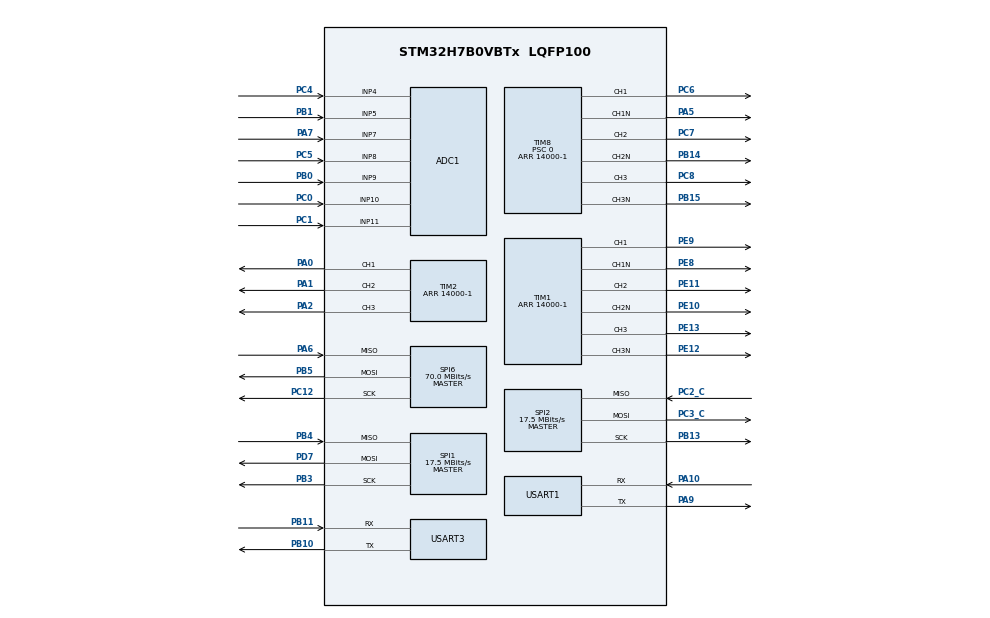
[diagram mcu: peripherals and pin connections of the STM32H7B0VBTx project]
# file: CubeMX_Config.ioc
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ADC1.Channel-0\#ChannelRegularConversion=ADC_CHANNEL_9
ADC1.Channel-1\#ChannelRegularConversion=ADC_CHANNEL_5
ADC1.Channel-2\#ChannelRegularConversion=ADC_CHANNEL_4
ADC1.Channel-3\#ChannelRegularConversion=ADC_CHANNEL_8
ADC1.Channel-4\#ChannelRegularConversion=ADC_CHANNEL_7
ADC1.Channel-5\#ChannelRegularConversion=ADC_CHANNEL_10
ADC1.Channel-6\#ChannelRegularConversion=ADC_CHANNEL_11
ADC1.ClockPrescaler=ADC_CLOCK_ASYNC_DIV2
ADC1.EnableAnalogWatchDog1=false
ADC1.ExternalTrigConv=ADC_EXTERNALTRIG_T1_TRGO
ADC1.NbrOfConversion=7
ADC1.NbrOfConversionFlag=1
ADC1.OffsetNumber-0\#ChannelRegularConversion=ADC_OFFSET_NONE
ADC1.OffsetNumber-1\#ChannelRegularConversion=ADC_OFFSET_NONE
ADC1.OffsetNumber-2\#ChannelRegularConversion=ADC_OFFSET_NONE
ADC1.OffsetNumber-3\#ChannelRegularConversion=ADC_OFFSET_NONE
ADC1.OffsetNumber-4\#ChannelRegularConversion=ADC_OFFSET_NONE
ADC1.OffsetNumber-5\#ChannelRegularConversion=ADC_OFFSET_NONE
ADC1.OffsetNumber-6\#ChannelRegularConversion=ADC_OFFSET_NONE
ADC1.OffsetSignedSaturation-0\#ChannelRegularConversion=DISABLE
ADC1.OffsetSignedSaturation-1\#ChannelRegularConversion=DISABLE
ADC1.OffsetSignedSaturation-2\#ChannelRegularConversion=DISABLE
ADC1.OffsetSignedSaturation-3\#ChannelRegularConversion=DISABLE
ADC1.OffsetSignedSaturation-4\#ChannelRegularConversion=DISABLE
ADC1.OffsetSignedSaturation-5\#ChannelRegularConversion=DISABLE
ADC1.OffsetSignedSaturation-6\#ChannelRegularConversion=DISABLE
ADC1.Rank-0\#ChannelRegularConversion=1
ADC1.Rank-1\#ChannelRegularConversion=2
ADC1.Rank-2\#ChannelRegularConversion=3
ADC1.Rank-3\#ChannelRegularConversion=4
ADC1.Rank-4\#ChannelRegularConversion=5
ADC1.Rank-5\#ChannelRegularConversion=6
ADC1.Rank-6\#ChannelRegularConversion=7
ADC1.SamplingTime-0\#ChannelRegularConversion=ADC_SAMPLETIME_1CYCLE_5
ADC1.SamplingTime-1\#ChannelRegularConversion=ADC_SAMPLETIME_1CYCLE_5
ADC1.SamplingTime-2\#ChannelRegularConversion=ADC_SAMPLETIME_1CYCLE_5
ADC1.SamplingTime-3\#ChannelRegularConversion=ADC_SAMPLETIME_1CYCLE_5
ADC1.SamplingTime-4\#ChannelRegularConversion=ADC_SAMPLETIME_1CYCLE_5
ADC1.SamplingTime-5\#ChannelRegularConversion=ADC_SAMPLETIME_1CYCLE_5
ADC1.SamplingTime-6\#ChannelRegularConversion=ADC_SAMPLETIME_1CYCLE_5
ADC1.master=1
CORTEX_M7.CPU_DCache=Enabled
CORTEX_M7.CPU_ICache=Enabled
Mcu.Family=STM32H7
Mcu.Name=STM32H7B0VBTx
Mcu.Package=LQFP100
NVIC.PriorityGroup=NVIC_PRIORITYGROUP_4
NVIC.TIM4_IRQn=true\:0\:0\:false\:false\:true\:true\:true\:true
PA0.GPIO_Speed=GPIO_SPEED_FREQ_VERY_HIGH
PA0.Signal=S_TIM2_CH1_ETR
PA1.GPIO_Speed=GPIO_SPEED_FREQ_VERY_HIGH
PA1.Signal=S_TIM2_CH2
PA10.GPIO_PuPd=GPIO_PULLUP
PA10.GPIO_Speed=GPIO_SPEED_FREQ_HIGH
PA10.Mode=Asynchronous
PA10.Signal=USART1_RX
PA13.Mode=Serial_Wire
PA13.Signal=DEBUG_JTMS-SWDIO
PA14.Mode=Serial_Wire
PA14.Signal=DEBUG_JTCK-SWCLK
PA2.GPIO_Speed=GPIO_SPEED_FREQ_VERY_HIGH
PA2.Signal=S_TIM2_CH3
PA5.GPIO_Speed=GPIO_SPEED_FREQ_VERY_HIGH
PA5.Mode=PWM Generation1 CH1 CH1N
PA5.Signal=TIM8_CH1N
PA6.Mode=Full_Duplex_Master
PA6.Signal=SPI6_MISO
PA7.Signal=ADCx_INP7
PA9.GPIO_PuPd=GPIO_PULLUP
PA9.GPIO_Speed=GPIO_SPEED_FREQ_HIGH
PA9.Mode=Asynchronous
PA9.Signal=USART1_TX
PB0.Signal=ADCx_INP9
PB1.Signal=ADCx_INP5
PB10.GPIO_PuPd=GPIO_PULLUP
PB10.GPIO_Speed=GPIO_SPEED_FREQ_HIGH
PB10.Mode=Asynchronous
PB10.Signal=USART3_TX
PB11.GPIO_PuPd=GPIO_PULLUP
PB11.GPIO_Speed=GPIO_SPEED_FREQ_HIGH
PB11.Mode=Asynchronous
PB11.Signal=USART3_RX
PB13.GPIO_PuPd=GPIO_PULLUP
PB13.GPIO_Speed=GPIO_SPEED_FREQ_VERY_HIGH
PB13.Mode=Full_Duplex_Master
PB13.Signal=SPI2_SCK
PB14.GPIO_Speed=GPIO_SPEED_FREQ_VERY_HIGH
PB14.Mode=PWM Generation2 CH2 CH2N
PB14.Signal=TIM8_CH2N
PB15.GPIO_Speed=GPIO_SPEED_FREQ_VERY_HIGH
PB15.Mode=PWM Generation3 CH3 CH3N
PB15.Signal=TIM8_CH3N
PB3.GPIO_PuPd=GPIO_PULLUP
PB3.GPIO_Speed=GPIO_SPEED_FREQ_HIGH
PB3.Mode=Full_Duplex_Master
PB3.Signal=SPI1_SCK
PB4.GPIO_PuPd=GPIO_PULLUP
PB4.GPIO_Speed=GPIO_SPEED_FREQ_HIGH
PB4.Mode=Full_Duplex_Master
PB4.Signal=SPI1_MISO
PB5.Mode=Full_Duplex_Master
PB5.Signal=SPI6_MOSI
PC0.Signal=ADCx_INP10
PC1.Signal=ADCx_INP11
PC12.Mode=Full_Duplex_Master
PC12.Signal=SPI6_SCK
PC2_C.GPIO_PuPd=GPIO_PULLUP
PC2_C.GPIO_Speed=GPIO_SPEED_FREQ_VERY_HIGH
PC2_C.Mode=Full_Duplex_Master
PC2_C.Signal=SPI2_MISO
PC3_C.GPIO_PuPd=GPIO_PULLUP
PC3_C.GPIO_Speed=GPIO_SPEED_FREQ_VERY_HIGH
PC3_C.Mode=Full_Duplex_Master
PC3_C.Signal=SPI2_MOSI
PC4.Signal=ADCx_INP4
PC5.Signal=ADCx_INP8
PC6.GPIO_Speed=GPIO_SPEED_FREQ_VERY_HIGH
PC6.Signal=S_TIM8_CH1
PC7.GPIO_Speed=GPIO_SPEED_FREQ_VERY_HIGH
PC7.Signal=S_TIM8_CH2
PC8.GPIO_Speed=GPIO_SPEED_FREQ_VERY_HIGH
PC8.Signal=S_TIM8_CH3
PD7.GPIO_PuPd=GPIO_PULLUP
PD7.GPIO_Speed=GPIO_SPEED_FREQ_HIGH
PD7.Mode=Full_Duplex_Master
PD7.Signal=SPI1_MOSI
PE10.GPIO_Speed=GPIO_SPEED_FREQ_VERY_HIGH
PE10.Mode=PWM Generation2 CH2 CH2N
PE10.Signal=TIM1_CH2N
PE11.GPIO_Speed=GPIO_SPEED_FREQ_VERY_HIGH
PE11.Signal=S_TIM1_CH2
PE12.GPIO_Speed=GPIO_SPEED_FREQ_VERY_HIGH
PE12.Mode=PWM Generation3 CH3 CH3N
PE12.Signal=TIM1_CH3N
PE13.GPIO_Speed=GPIO_SPEED_FREQ_VERY_HIGH
PE13.Signal=S_TIM1_CH3
PE8.GPIO_Speed=GPIO_SPEED_FREQ_VERY_HIGH
PE8.Mode=PWM Generation1 CH1 CH1N
PE8.Signal=TIM1_CH1N
PE9.GPIO_Speed=GPIO_SPEED_FREQ_VERY_HIGH
PE9.Signal=S_TIM1_CH1
PH0-OSC_IN.Mode=HSE-External-Oscillator
PH0-OSC_IN.Signal=RCC_OSC_IN
PH1-OSC_OUT.Mode=HSE-External-Oscillator
PH1-OSC_OUT.Signal=RCC_OSC_OUT
ProjectManager.HeapSize=0x200
ProjectManager.StackSize=0x400
ProjectManager.TargetToolchain=MDK-ARM V5.32
RCC.ADCFreq_Value=42667100.69444445
RCC.APB1Freq_Value=140000000
RCC.APB2Freq_Value=140000000
RCC.APB3Freq_Value=140000000
RCC.APB4Freq_Value=140000000
RCC.CDPPRE=RCC_APB3_DIV2
RCC.CDPPRE1=RCC_APB1_DIV2
RCC.CDPPRE2=RCC_APB2_DIV2
RCC.CKPERSourceSelection=RCC_CLKPSOURCE_HSE
RCC.CortexFreq_Value=280000000
RCC.DIVM1=3
RCC.DIVM2=3
RCC.DIVN1=42
RCC.DIVN2=9
RCC.DIVP2=3
RCC.DIVQ1=4
RCC.HCLKFreq_Value=280000000
RCC.HSE_VALUE=40000000
RCC.PLL2FRACN=4916
RCC.PLL3FRACN=0
RCC.PLLFRACN=0
RCC.PLLSourceVirtual=RCC_PLLSOURCE_HSE
RCC.SRDPPRE=RCC_APB4_DIV2
RCC.SYSCLKFreq_VALUE=280000000
RCC.SYSCLKSource=RCC_SYSCLKSOURCE_PLLCLK
RCC.USBFreq_Value=140000000
SH.ADCx_INP10.0=ADC1_INP10,IN10-Single-Ended
SH.ADCx_INP11.0=ADC1_INP11,IN11-Single-Ended
SH.ADCx_INP4.0=ADC1_INP4,IN4-Single-Ended
SH.ADCx_INP5.0=ADC1_INP5,IN5-Single-Ended
SH.ADCx_INP7.0=ADC1_INP7,IN7-Single-Ended
SH.ADCx_INP8.0=ADC1_INP8,IN8-Single-Ended
SH.ADCx_INP9.0=ADC1_INP9,IN9-Single-Ended
SH.S_TIM1_CH1.0=TIM1_CH1,PWM Generation1 CH1 CH1N
SH.S_TIM1_CH2.0=TIM1_CH2,PWM Generation2 CH2 CH2N
SH.S_TIM1_CH3.0=TIM1_CH3,PWM Generation3 CH3 CH3N
SH.S_TIM2_CH1_ETR.0=TIM2_CH1,PWM Generation1 CH1
SH.S_TIM2_CH2.0=TIM2_CH2,PWM Generation2 CH2
SH.S_TIM2_CH3.0=TIM2_CH3,PWM Generation3 CH3
SH.S_TIM8_CH1.0=TIM8_CH1,PWM Generation1 CH1 CH1N
SH.S_TIM8_CH2.0=TIM8_CH2,PWM Generation2 CH2 CH2N
SH.S_TIM8_CH3.0=TIM8_CH3,PWM Generation3 CH3 CH3N
SPI1.BaudRatePrescaler=SPI_BAUDRATEPRESCALER_8
SPI1.CLKPhase=SPI_PHASE_2EDGE
SPI1.CLKPolarity=SPI_POLARITY_HIGH
SPI1.CalculateBaudRate=17.5 MBits/s
SPI1.Direction=SPI_DIRECTION_2LINES
SPI1.Mode=SPI_MODE_MASTER
SPI1.VirtualType=VM_MASTER
SPI2.BaudRatePrescaler=SPI_BAUDRATEPRESCALER_8
SPI2.CalculateBaudRate=17.5 MBits/s
SPI2.Direction=SPI_DIRECTION_2LINES
SPI2.IOSwap=SPI_IO_SWAP_ENABLE
SPI2.Mode=SPI_MODE_MASTER
SPI2.VirtualType=VM_MASTER
SPI6.CalculateBaudRate=70.0 MBits/s
SPI6.Direction=SPI_DIRECTION_2LINES
SPI6.Mode=SPI_MODE_MASTER
SPI6.VirtualType=VM_MASTER
TIM1.Channel-PWM\ Generation1\ CH1\ CH1N=TIM_CHANNEL_1
TIM1.Channel-PWM\ Generation2\ CH2\ CH2N=TIM_CHANNEL_2
TIM1.Channel-PWM\ Generation3\ CH3\ CH3N=TIM_CHANNEL_3
TIM1.Channel-PWM\ Generation4\ No\ Output=TIM_CHANNEL_4
TIM1.CounterMode=TIM_COUNTERMODE_CENTERALIGNED1
TIM1.OCMode_PWM-PWM\ Generation4\ No\ Output=TIM_OCMODE_PWM2
TIM1.Period=14000-1
TIM1.TIM_MasterOutputTrigger=TIM_TRGO_OC4REF
TIM2.Channel-PWM\ Generation1\ CH1=TIM_CHANNEL_1
TIM2.Channel-PWM\ Generation2\ CH2=TIM_CHANNEL_2
TIM2.Channel-PWM\ Generation3\ CH3=TIM_CHANNEL_3
TIM2.Period=14000-1
TIM2.Pulse-PWM\ Generation1\ CH1=7000-1
TIM2.Pulse-PWM\ Generation2\ CH2=7000-1
TIM2.Pulse-PWM\ Generation3\ CH3=7000-1
TIM8.AutomaticOutput=TIM_AUTOMATICOUTPUT_ENABLE
TIM8.Channel-PWM\ Generation1\ CH1\ CH1N=TIM_CHANNEL_1
TIM8.Channel-PWM\ Generation2\ CH2\ CH2N=TIM_CHANNEL_2
TIM8.Channel-PWM\ Generation3\ CH3\ CH3N=TIM_CHANNEL_3
TIM8.DeadTime=48
TIM8.LockLevel=TIM_LOCKLEVEL_3
TIM8.Period=14000-1
TIM8.Prescaler=0
TIM8.Pulse-PWM\ Generation1\ CH1\ CH1N=7000-1
USART1.VirtualMode-Asynchronous=VM_ASYNC
USART3.VirtualMode-Asynchronous=VM_ASYNC
VP_TIM1_VS_ClockSourceINT.Mode=Internal
VP_TIM1_VS_no_output4.Mode=PWM Generation4 No Output
VP_TIM2_VS_ClockSourceINT.Mode=Internal
VP_TIM4_VS_ClockSourceINT.Mode=Internal
VP_TIM8_VS_ClockSourceINT.Mode=Internal
board=custom

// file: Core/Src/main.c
/* USER CODE BEGIN Header */
/**
  ******************************************************************************
  * @file           : main.c
  * @brief          : Main program body
  ******************************************************************************
  * @attention
  *
  * Copyright (c) 2024 STMicroelectronics.
  * All rights reserved.
  *
  * This software is licensed under terms that can be found in the LICENSE file
  * in the root directory of this software component.
  * If no LICENSE file comes with this software, it is provided AS-IS.
  *
  ******************************************************************************
  */
/* USER CODE END Header */
#include "main.h"

ADC_HandleTypeDef hadc1;

SPI_HandleTypeDef hspi1;
SPI_HandleTypeDef hspi2;
SPI_HandleTypeDef hspi6;

TIM_HandleTypeDef htim1;
TIM_HandleTypeDef htim2;
TIM_HandleTypeDef htim4;
TIM_HandleTypeDef htim8;

UART_HandleTypeDef huart1;
UART_HandleTypeDef huart3;

void SystemClock_Config(void);
static void MX_GPIO_Init(void);
static void MX_USART3_UART_Init(void);
static void MX_SPI1_Init(void);
static void MX_SPI6_Init(void);
static void MX_USART1_UART_Init(void);
static void MX_TIM8_Init(void);
static void MX_TIM1_Init(void);
static void MX_TIM2_Init(void);
static void MX_ADC1_Init(void);
static void MX_SPI2_Init(void);
static void MX_TIM4_Init(void);

int main(void)
{

  /* Enable I-Cache---------------------------------------------------------*/
  SCB_EnableICache();

  /* Enable D-Cache---------------------------------------------------------*/
  SCB_EnableDCache();

  /* MCU Configuration--------------------------------------------------------*/

  /* Reset of all peripherals, Initializes the Flash interface and the Systick. */
  HAL_Init();

  /* Configure the system clock */
  SystemClock_Config();

  /* Initialize all configured peripherals */
  MX_GPIO_Init();
  MX_USART3_UART_Init();
  MX_SPI1_Init();
  MX_SPI6_Init();
  MX_USART1_UART_Init();
  MX_TIM8_Init();
  MX_TIM1_Init();
  MX_TIM2_Init();
  MX_ADC1_Init();
  MX_SPI2_Init();
  MX_TIM4_Init();

  /* Infinite loop */
  while (1)
  {

  }
}

void SystemClock_Config(void)
{
  RCC_OscInitTypeDef RCC_OscInitStruct = {0};
  RCC_ClkInitTypeDef RCC_ClkInitStruct = {0};

  /*AXI clock gating */
  RCC->CKGAENR = 0xFFFFFFFF;

  /** Supply configuration update enable
  */
  HAL_PWREx_ConfigSupply(PWR_LDO_SUPPLY);

  /** Configure the main internal regulator output voltage
  */
  __HAL_PWR_VOLTAGESCALING_CONFIG(PWR_REGULATOR_VOLTAGE_SCALE0);

  while(!__HAL_PWR_GET_FLAG(PWR_FLAG_VOSRDY)) {}

  /** Initializes the RCC Oscillators according to the specified parameters
  * in the RCC_OscInitTypeDef structure.
  */
  RCC_OscInitStruct.OscillatorType = RCC_OSCILLATORTYPE_HSE;
  RCC_OscInitStruct.HSEState = RCC_HSE_ON;
  RCC_OscInitStruct.PLL.PLLState = RCC_PLL_ON;
  RCC_OscInitStruct.PLL.PLLSource = RCC_PLLSOURCE_HSE;
  RCC_OscInitStruct.PLL.PLLM = 3;
  RCC_OscInitStruct.PLL.PLLN = 42;
  RCC_OscInitStruct.PLL.PLLP = 2;
  RCC_OscInitStruct.PLL.PLLQ = 4;
  RCC_OscInitStruct.PLL.PLLR = 2;
  RCC_OscInitStruct.PLL.PLLRGE = RCC_PLL1VCIRANGE_3;
  RCC_OscInitStruct.PLL.PLLVCOSEL = RCC_PLL1VCOWIDE;
  RCC_OscInitStruct.PLL.PLLFRACN = 0;
  if (HAL_RCC_OscConfig(&RCC_OscInitStruct) != HAL_OK)
  {
    Error_Handler();
  }

  /** Initializes the CPU, AHB and APB buses clocks
  */
  RCC_ClkInitStruct.ClockType = RCC_CLOCKTYPE_HCLK|RCC_CLOCKTYPE_SYSCLK
                              |RCC_CLOCKTYPE_PCLK1|RCC_CLOCKTYPE_PCLK2
                              |RCC_CLOCKTYPE_D3PCLK1|RCC_CLOCKTYPE_D1PCLK1;
  RCC_ClkInitStruct.SYSCLKSource = RCC_SYSCLKSOURCE_PLLCLK;
  RCC_ClkInitStruct.SYSCLKDivider = RCC_SYSCLK_DIV1;
  RCC_ClkInitStruct.AHBCLKDivider = RCC_HCLK_DIV1;
  RCC_ClkInitStruct.APB3CLKDivider = RCC_APB3_DIV2;
  RCC_ClkInitStruct.APB1CLKDivider = RCC_APB1_DIV2;
  RCC_ClkInitStruct.APB2CLKDivider = RCC_APB2_DIV2;
  RCC_ClkInitStruct.APB4CLKDivider = RCC_APB4_DIV2;

  if (HAL_RCC_ClockConfig(&RCC_ClkInitStruct, FLASH_LATENCY_6) != HAL_OK)
  {
    Error_Handler();
  }
}

static void MX_ADC1_Init(void)
{

  ADC_MultiModeTypeDef multimode = {0};
  ADC_ChannelConfTypeDef sConfig = {0};

  /** Common config
  */
  hadc1.Instance = ADC1;
  hadc1.Init.ClockPrescaler = ADC_CLOCK_ASYNC_DIV2;
  hadc1.Init.Resolution = ADC_RESOLUTION_16B;
  hadc1.Init.ScanConvMode = ADC_SCAN_ENABLE;
  hadc1.Init.EOCSelection = ADC_EOC_SINGLE_CONV;
  hadc1.Init.LowPowerAutoWait = DISABLE;
  hadc1.Init.ContinuousConvMode = DISABLE;
  hadc1.Init.NbrOfConversion = 7;
  hadc1.Init.DiscontinuousConvMode = DISABLE;
  hadc1.Init.ExternalTrigConv = ADC_EXTERNALTRIG_T1_TRGO;
  hadc1.Init.ExternalTrigConvEdge = ADC_EXTERNALTRIGCONVEDGE_RISING;
  hadc1.Init.ConversionDataManagement = ADC_CONVERSIONDATA_DR;
  hadc1.Init.Overrun = ADC_OVR_DATA_PRESERVED;
  hadc1.Init.LeftBitShift = ADC_LEFTBITSHIFT_NONE;
  hadc1.Init.OversamplingMode = DISABLE;
  if (HAL_ADC_Init(&hadc1) != HAL_OK)
  {
    Error_Handler();
  }

  /** Configure the ADC multi-mode
  */
  multimode.Mode = ADC_MODE_INDEPENDENT;
  if (HAL_ADCEx_MultiModeConfigChannel(&hadc1, &multimode) != HAL_OK)
  {
    Error_Handler();
  }

  /** Configure Regular Channel
  */
  sConfig.Channel = ADC_CHANNEL_9;
  sConfig.Rank = ADC_REGULAR_RANK_1;
  sConfig.SamplingTime = ADC_SAMPLETIME_1CYCLE_5;
  sConfig.SingleDiff = ADC_SINGLE_ENDED;
  sConfig.OffsetNumber = ADC_OFFSET_NONE;
  sConfig.Offset = 0;
  sConfig.OffsetSignedSaturation = DISABLE;
  if (HAL_ADC_ConfigChannel(&hadc1, &sConfig) != HAL_OK)
  {
    Error_Handler();
  }

  /** Configure Regular Channel
  */
  sConfig.Channel = ADC_CHANNEL_5;
  sConfig.Rank = ADC_REGULAR_RANK_2;
  if (HAL_ADC_ConfigChannel(&hadc1, &sConfig) != HAL_OK)
  {
    Error_Handler();
  }

  /** Configure Regular Channel
  */
  sConfig.Channel = ADC_CHANNEL_4;
  sConfig.Rank = ADC_REGULAR_RANK_3;
  if (HAL_ADC_ConfigChannel(&hadc1, &sConfig) != HAL_OK)
  {
    Error_Handler();
  }

  /** Configure Regular Channel
  */
  sConfig.Channel = ADC_CHANNEL_8;
  sConfig.Rank = ADC_REGULAR_RANK_4;
  if (HAL_ADC_ConfigChannel(&hadc1, &sConfig) != HAL_OK)
  {
    Error_Handler();
  }

  /** Configure Regular Channel
  */
  sConfig.Channel = ADC_CHANNEL_7;
  sConfig.Rank = ADC_REGULAR_RANK_5;
  if (HAL_ADC_ConfigChannel(&hadc1, &sConfig) != HAL_OK)
  {
    Error_Handler();
  }

  /** Configure Regular Channel
  */
  sConfig.Channel = ADC_CHANNEL_10;
  sConfig.Rank = ADC_REGULAR_RANK_6;
  if (HAL_ADC_ConfigChannel(&hadc1, &sConfig) != HAL_OK)
  {
    Error_Handler();
  }

  /** Configure Regular Channel
  */
  sConfig.Channel = ADC_CHANNEL_11;
  sConfig.Rank = ADC_REGULAR_RANK_7;
  if (HAL_ADC_ConfigChannel(&hadc1, &sConfig) != HAL_OK)
  {
    Error_Handler();
  }

}

static void MX_SPI1_Init(void)
{

  /* SPI1 parameter configuration*/
  hspi1.Instance = SPI1;
  hspi1.Init.Mode = SPI_MODE_MASTER;
  hspi1.Init.Direction = SPI_DIRECTION_2LINES;
  hspi1.Init.DataSize = SPI_DATASIZE_4BIT;
  hspi1.Init.CLKPolarity = SPI_POLARITY_HIGH;
  hspi1.Init.CLKPhase = SPI_PHASE_2EDGE;
  hspi1.Init.NSS = SPI_NSS_SOFT;
  hspi1.Init.BaudRatePrescaler = SPI_BAUDRATEPRESCALER_8;
  hspi1.Init.FirstBit = SPI_FIRSTBIT_MSB;
  hspi1.Init.TIMode = SPI_TIMODE_DISABLE;
  hspi1.Init.CRCCalculation = SPI_CRCCALCULATION_DISABLE;
  hspi1.Init.CRCPolynomial = 0x0;
  hspi1.Init.NSSPMode = SPI_NSS_PULSE_ENABLE;
  hspi1.Init.NSSPolarity = SPI_NSS_POLARITY_LOW;
  hspi1.Init.FifoThreshold = SPI_FIFO_THRESHOLD_01DATA;
  hspi1.Init.TxCRCInitializationPattern = SPI_CRC_INITIALIZATION_ALL_ZERO_PATTERN;
  hspi1.Init.RxCRCInitializationPattern = SPI_CRC_INITIALIZATION_ALL_ZERO_PATTERN;
  hspi1.Init.MasterSSIdleness = SPI_MASTER_SS_IDLENESS_00CYCLE;
  hspi1.Init.MasterInterDataIdleness = SPI_MASTER_INTERDATA_IDLENESS_00CYCLE;
  hspi1.Init.MasterReceiverAutoSusp = SPI_MASTER_RX_AUTOSUSP_DISABLE;
  hspi1.Init.MasterKeepIOState = SPI_MASTER_KEEP_IO_STATE_DISABLE;
  hspi1.Init.IOSwap = SPI_IO_SWAP_DISABLE;
  if (HAL_SPI_Init(&hspi1) != HAL_OK)
  {
    Error_Handler();
  }

}

static void MX_SPI2_Init(void)
{

  /* SPI2 parameter configuration*/
  hspi2.Instance = SPI2;
  hspi2.Init.Mode = SPI_MODE_MASTER;
  hspi2.Init.Direction = SPI_DIRECTION_2LINES;
  hspi2.Init.DataSize = SPI_DATASIZE_4BIT;
  hspi2.Init.CLKPolarity = SPI_POLARITY_LOW;
  hspi2.Init.CLKPhase = SPI_PHASE_1EDGE;
  hspi2.Init.NSS = SPI_NSS_SOFT;
  hspi2.Init.BaudRatePrescaler = SPI_BAUDRATEPRESCALER_8;
  hspi2.Init.FirstBit = SPI_FIRSTBIT_MSB;
  hspi2.Init.TIMode = SPI_TIMODE_DISABLE;
  hspi2.Init.CRCCalculation = SPI_CRCCALCULATION_DISABLE;
  hspi2.Init.CRCPolynomial = 0x0;
  hspi2.Init.NSSPMode = SPI_NSS_PULSE_ENABLE;
  hspi2.Init.NSSPolarity = SPI_NSS_POLARITY_LOW;
  hspi2.Init.FifoThreshold = SPI_FIFO_THRESHOLD_01DATA;
  hspi2.Init.TxCRCInitializationPattern = SPI_CRC_INITIALIZATION_ALL_ZERO_PATTERN;
  hspi2.Init.RxCRCInitializationPattern = SPI_CRC_INITIALIZATION_ALL_ZERO_PATTERN;
  hspi2.Init.MasterSSIdleness = SPI_MASTER_SS_IDLENESS_00CYCLE;
  hspi2.Init.MasterInterDataIdleness = SPI_MASTER_INTERDATA_IDLENESS_00CYCLE;
  hspi2.Init.MasterReceiverAutoSusp = SPI_MASTER_RX_AUTOSUSP_DISABLE;
  hspi2.Init.MasterKeepIOState = SPI_MASTER_KEEP_IO_STATE_DISABLE;
  hspi2.Init.IOSwap = SPI_IO_SWAP_ENABLE;
  if (HAL_SPI_Init(&hspi2) != HAL_OK)
  {
    Error_Handler();
  }

}

static void MX_SPI6_Init(void)
{

  /* SPI6 parameter configuration*/
  hspi6.Instance = SPI6;
  hspi6.Init.Mode = SPI_MODE_MASTER;
  hspi6.Init.Direction = SPI_DIRECTION_2LINES;
  hspi6.Init.DataSize = SPI_DATASIZE_4BIT;
  hspi6.Init.CLKPolarity = SPI_POLARITY_LOW;
  hspi6.Init.CLKPhase = SPI_PHASE_1EDGE;
  hspi6.Init.NSS = SPI_NSS_SOFT;
  hspi6.Init.BaudRatePrescaler = SPI_BAUDRATEPRESCALER_2;
  hspi6.Init.FirstBit = SPI_FIRSTBIT_MSB;
  hspi6.Init.TIMode = SPI_TIMODE_DISABLE;
  hspi6.Init.CRCCalculation = SPI_CRCCALCULATION_DISABLE;
  hspi6.Init.CRCPolynomial = 0x0;
  hspi6.Init.NSSPMode = SPI_NSS_PULSE_ENABLE;
  hspi6.Init.NSSPolarity = SPI_NSS_POLARITY_LOW;
  hspi6.Init.FifoThreshold = SPI_FIFO_THRESHOLD_01DATA;
  hspi6.Init.TxCRCInitializationPattern = SPI_CRC_INITIALIZATION_ALL_ZERO_PATTERN;
  hspi6.Init.RxCRCInitializationPattern = SPI_CRC_INITIALIZATION_ALL_ZERO_PATTERN;
  hspi6.Init.MasterSSIdleness = SPI_MASTER_SS_IDLENESS_00CYCLE;
  hspi6.Init.MasterInterDataIdleness = SPI_MASTER_INTERDATA_IDLENESS_00CYCLE;
  hspi6.Init.MasterReceiverAutoSusp = SPI_MASTER_RX_AUTOSUSP_DISABLE;
  hspi6.Init.MasterKeepIOState = SPI_MASTER_KEEP_IO_STATE_DISABLE;
  hspi6.Init.IOSwap = SPI_IO_SWAP_DISABLE;
  if (HAL_SPI_Init(&hspi6) != HAL_OK)
  {
    Error_Handler();
  }

}

static void MX_TIM1_Init(void)
{

  TIM_ClockConfigTypeDef sClockSourceConfig = {0};
  TIM_MasterConfigTypeDef sMasterConfig = {0};
  TIM_OC_InitTypeDef sConfigOC = {0};
  TIM_BreakDeadTimeConfigTypeDef sBreakDeadTimeConfig = {0};

  htim1.Instance = TIM1;
  htim1.Init.Prescaler = 0;
  htim1.Init.CounterMode = TIM_COUNTERMODE_CENTERALIGNED1;
  htim1.Init.Period = 14000-1;
  htim1.Init.ClockDivision = TIM_CLOCKDIVISION_DIV1;
  htim1.Init.RepetitionCounter = 0;
  htim1.Init.AutoReloadPreload = TIM_AUTORELOAD_PRELOAD_DISABLE;
  if (HAL_TIM_Base_Init(&htim1) != HAL_OK)
  {
    Error_Handler();
  }
  sClockSourceConfig.ClockSource = TIM_CLOCKSOURCE_INTERNAL;
  if (HAL_TIM_ConfigClockSource(&htim1, &sClockSourceConfig) != HAL_OK)
  {
    Error_Handler();
  }
  if (HAL_TIM_PWM_Init(&htim1) != HAL_OK)
  {
    Error_Handler();
  }
  sMasterConfig.MasterOutputTrigger = TIM_TRGO_OC4REF;
  sMasterConfig.MasterOutputTrigger2 = TIM_TRGO2_RESET;
  sMasterConfig.MasterSlaveMode = TIM_MASTERSLAVEMODE_DISABLE;
  if (HAL_TIMEx_MasterConfigSynchronization(&htim1, &sMasterConfig) != HAL_OK)
  {
    Error_Handler();
  }
  sConfigOC.OCMode = TIM_OCMODE_PWM1;
  sConfigOC.Pulse = 0;
  sConfigOC.OCPolarity = TIM_OCPOLARITY_HIGH;
  sConfigOC.OCNPolarity = TIM_OCNPOLARITY_HIGH;
  sConfigOC.OCFastMode = TIM_OCFAST_DISABLE;
  sConfigOC.OCIdleState = TIM_OCIDLESTATE_RESET;
  sConfigOC.OCNIdleState = TIM_OCNIDLESTATE_RESET;
  if (HAL_TIM_PWM_ConfigChannel(&htim1, &sConfigOC, TIM_CHANNEL_1) != HAL_OK)
  {
    Error_Handler();
  }
  if (HAL_TIM_PWM_ConfigChannel(&htim1, &sConfigOC, TIM_CHANNEL_2) != HAL_OK)
  {
    Error_Handler();
  }
  if (HAL_TIM_PWM_ConfigChannel(&htim1, &sConfigOC, TIM_CHANNEL_3) != HAL_OK)
  {
    Error_Handler();
  }
  sConfigOC.OCMode = TIM_OCMODE_PWM2;
  if (HAL_TIM_PWM_ConfigChannel(&htim1, &sConfigOC, TIM_CHANNEL_4) != HAL_OK)
  {
    Error_Handler();
  }
  sBreakDeadTimeConfig.OffStateRunMode = TIM_OSSR_DISABLE;
  sBreakDeadTimeConfig.OffStateIDLEMode = TIM_OSSI_DISABLE;
  sBreakDeadTimeConfig.LockLevel = TIM_LOCKLEVEL_OFF;
  sBreakDeadTimeConfig.DeadTime = 0;
  sBreakDeadTimeConfig.BreakState = TIM_BREAK_DISABLE;
  sBreakDeadTimeConfig.BreakPolarity = TIM_BREAKPOLARITY_HIGH;
  sBreakDeadTimeConfig.BreakFilter = 0;
  sBreakDeadTimeConfig.Break2State = TIM_BREAK2_DISABLE;
  sBreakDeadTimeConfig.Break2Polarity = TIM_BREAK2POLARITY_HIGH;
  sBreakDeadTimeConfig.Break2Filter = 0;
  sBreakDeadTimeConfig.AutomaticOutput = TIM_AUTOMATICOUTPUT_DISABLE;
  if (HAL_TIMEx_ConfigBreakDeadTime(&htim1, &sBreakDeadTimeConfig) != HAL_OK)
  {
    Error_Handler();
  }
  HAL_TIM_MspPostInit(&htim1);

}

static void MX_TIM2_Init(void)
{

  TIM_ClockConfigTypeDef sClockSourceConfig = {0};
  TIM_MasterConfigTypeDef sMasterConfig = {0};
  TIM_OC_InitTypeDef sConfigOC = {0};

  htim2.Instance = TIM2;
  htim2.Init.Prescaler = 0;
  htim2.Init.CounterMode = TIM_COUNTERMODE_UP;
  htim2.Init.Period = 14000-1;
  htim2.Init.ClockDivision = TIM_CLOCKDIVISION_DIV1;
  htim2.Init.AutoReloadPreload = TIM_AUTORELOAD_PRELOAD_DISABLE;
  if (HAL_TIM_Base_Init(&htim2) != HAL_OK)
  {
    Error_Handler();
  }
  sClockSourceConfig.ClockSource = TIM_CLOCKSOURCE_INTERNAL;
  if (HAL_TIM_ConfigClockSource(&htim2, &sClockSourceConfig) != HAL_OK)
  {
    Error_Handler();
  }
  if (HAL_TIM_PWM_Init(&htim2) != HAL_OK)
  {
    Error_Handler();
  }
  sMasterConfig.MasterOutputTrigger = TIM_TRGO_RESET;
  sMasterConfig.MasterSlaveMode = TIM_MASTERSLAVEMODE_DISABLE;
  if (HAL_TIMEx_MasterConfigSynchronization(&htim2, &sMasterConfig) != HAL_OK)
  {
    Error_Handler();
  }
  sConfigOC.OCMode = TIM_OCMODE_PWM1;
  sConfigOC.Pulse = 7000-1;
  sConfigOC.OCPolarity = TIM_OCPOLARITY_HIGH;
  sConfigOC.OCFastMode = TIM_OCFAST_DISABLE;
  if (HAL_TIM_PWM_ConfigChannel(&htim2, &sConfigOC, TIM_CHANNEL_1) != HAL_OK)
  {
    Error_Handler();
  }
  if (HAL_TIM_PWM_ConfigChannel(&htim2, &sConfigOC, TIM_CHANNEL_2) != HAL_OK)
  {
    Error_Handler();
  }
  if (HAL_TIM_PWM_ConfigChannel(&htim2, &sConfigOC, TIM_CHANNEL_3) != HAL_OK)
  {
    Error_Handler();
  }
  HAL_TIM_MspPostInit(&htim2);

}

static void MX_TIM4_Init(void)
{

  TIM_ClockConfigTypeDef sClockSourceConfig = {0};
  TIM_MasterConfigTypeDef sMasterConfig = {0};

  htim4.Instance = TIM4;
  htim4.Init.Prescaler = 0;
  htim4.Init.CounterMode = TIM_COUNTERMODE_UP;
  htim4.Init.Period = 65535;
  htim4.Init.ClockDivision = TIM_CLOCKDIVISION_DIV1;
  htim4.Init.AutoReloadPreload = TIM_AUTORELOAD_PRELOAD_DISABLE;
  if (HAL_TIM_Base_Init(&htim4) != HAL_OK)
  {
    Error_Handler();
  }
  sClockSourceConfig.ClockSource = TIM_CLOCKSOURCE_INTERNAL;
  if (HAL_TIM_ConfigClockSource(&htim4, &sClockSourceConfig) != HAL_OK)
  {
    Error_Handler();
  }
  sMasterConfig.MasterOutputTrigger = TIM_TRGO_RESET;
  sMasterConfig.MasterSlaveMode = TIM_MASTERSLAVEMODE_DISABLE;
  if (HAL_TIMEx_MasterConfigSynchronization(&htim4, &sMasterConfig) != HAL_OK)
  {
    Error_Handler();
  }

}

static void MX_TIM8_Init(void)
{

  TIM_ClockConfigTypeDef sClockSourceConfig = {0};
  TIM_MasterConfigTypeDef sMasterConfig = {0};
  TIM_OC_InitTypeDef sConfigOC = {0};
  TIM_BreakDeadTimeConfigTypeDef sBreakDeadTimeConfig = {0};

  htim8.Instance = TIM8;
  htim8.Init.Prescaler = 0;
  htim8.Init.CounterMode = TIM_COUNTERMODE_UP;
  htim8.Init.Period = 14000-1;
  htim8.Init.ClockDivision = TIM_CLOCKDIVISION_DIV1;
  htim8.Init.RepetitionCounter = 0;
  htim8.Init.AutoReloadPreload = TIM_AUTORELOAD_PRELOAD_DISABLE;
  if (HAL_TIM_Base_Init(&htim8) != HAL_OK)
  {
    Error_Handler();
  }
  sClockSourceConfig.ClockSource = TIM_CLOCKSOURCE_INTERNAL;
  if (HAL_TIM_ConfigClockSource(&htim8, &sClockSourceConfig) != HAL_OK)
  {
    Error_Handler();
  }
  if (HAL_TIM_PWM_Init(&htim8) != HAL_OK)
  {
    Error_Handler();
  }
  sMasterConfig.MasterOutputTrigger = TIM_TRGO_RESET;
  sMasterConfig.MasterOutputTrigger2 = TIM_TRGO2_RESET;
  sMasterConfig.MasterSlaveMode = TIM_MASTERSLAVEMODE_DISABLE;
  if (HAL_TIMEx_MasterConfigSynchronization(&htim8, &sMasterConfig) != HAL_OK)
  {
    Error_Handler();
  }
  sConfigOC.OCMode = TIM_OCMODE_PWM1;
  sConfigOC.Pulse = 7000-1;
  sConfigOC.OCPolarity = TIM_OCPOLARITY_HIGH;
  sConfigOC.OCNPolarity = TIM_OCNPOLARITY_HIGH;
  sConfigOC.OCFastMode = TIM_OCFAST_DISABLE;
  sConfigOC.OCIdleState = TIM_OCIDLESTATE_RESET;
  sConfigOC.OCNIdleState = TIM_OCNIDLESTATE_RESET;
  if (HAL_TIM_PWM_ConfigChannel(&htim8, &sConfigOC, TIM_CHANNEL_1) != HAL_OK)
  {
    Error_Handler();
  }
  sConfigOC.Pulse = 0;
  if (HAL_TIM_PWM_ConfigChannel(&htim8, &sConfigOC, TIM_CHANNEL_2) != HAL_OK)
  {
    Error_Handler();
  }
  if (HAL_TIM_PWM_ConfigChannel(&htim8, &sConfigOC, TIM_CHANNEL_3) != HAL_OK)
  {
    Error_Handler();
  }
  sBreakDeadTimeConfig.OffStateRunMode = TIM_OSSR_DISABLE;
  sBreakDeadTimeConfig.OffStateIDLEMode = TIM_OSSI_DISABLE;
  sBreakDeadTimeConfig.LockLevel = TIM_LOCKLEVEL_3;
  sBreakDeadTimeConfig.DeadTime = 48;
  sBreakDeadTimeConfig.BreakState = TIM_BREAK_DISABLE;
  sBreakDeadTimeConfig.BreakPolarity = TIM_BREAKPOLARITY_HIGH;
  sBreakDeadTimeConfig.BreakFilter = 0;
  sBreakDeadTimeConfig.Break2State = TIM_BREAK2_DISABLE;
  sBreakDeadTimeConfig.Break2Polarity = TIM_BREAK2POLARITY_HIGH;
  sBreakDeadTimeConfig.Break2Filter = 0;
  sBreakDeadTimeConfig.AutomaticOutput = TIM_AUTOMATICOUTPUT_ENABLE;
  if (HAL_TIMEx_ConfigBreakDeadTime(&htim8, &sBreakDeadTimeConfig) != HAL_OK)
  {
    Error_Handler();
  }
  HAL_TIM_MspPostInit(&htim8);

}

static void MX_USART1_UART_Init(void)
{

  huart1.Instance = USART1;
  huart1.Init.BaudRate = 115200;
  huart1.Init.WordLength = UART_WORDLENGTH_8B;
  huart1.Init.StopBits = UART_STOPBITS_1;
  huart1.Init.Parity = UART_PARITY_NONE;
  huart1.Init.Mode = UART_MODE_TX_RX;
  huart1.Init.HwFlowCtl = UART_HWCONTROL_NONE;
  huart1.Init.OverSampling = UART_OVERSAMPLING_16;
  huart1.Init.OneBitSampling = UART_ONE_BIT_SAMPLE_DISABLE;
  huart1.Init.ClockPrescaler = UART_PRESCALER_DIV1;
  huart1.AdvancedInit.AdvFeatureInit = UART_ADVFEATURE_NO_INIT;
  if (HAL_UART_Init(&huart1) != HAL_OK)
  {
    Error_Handler();
  }
  if (HAL_UARTEx_SetTxFifoThreshold(&huart1, UART_TXFIFO_THRESHOLD_1_8) != HAL_OK)
  {
    Error_Handler();
  }
  if (HAL_UARTEx_SetRxFifoThreshold(&huart1, UART_RXFIFO_THRESHOLD_1_8) != HAL_OK)
  {
    Error_Handler();
  }
  if (HAL_UARTEx_DisableFifoMode(&huart1) != HAL_OK)
  {
    Error_Handler();
  }

}

static void MX_USART3_UART_Init(void)
{

  huart3.Instance = USART3;
  huart3.Init.BaudRate = 115200;
  huart3.Init.WordLength = UART_WORDLENGTH_8B;
  huart3.Init.StopBits = UART_STOPBITS_1;
  huart3.Init.Parity = UART_PARITY_NONE;
  huart3.Init.Mode = UART_MODE_TX_RX;
  huart3.Init.HwFlowCtl = UART_HWCONTROL_NONE;
  huart3.Init.OverSampling = UART_OVERSAMPLING_16;
  huart3.Init.OneBitSampling = UART_ONE_BIT_SAMPLE_DISABLE;
  huart3.Init.ClockPrescaler = UART_PRESCALER_DIV1;
  huart3.AdvancedInit.AdvFeatureInit = UART_ADVFEATURE_NO_INIT;
  if (HAL_UART_Init(&huart3) != HAL_OK)
  {
    Error_Handler();
  }
  if (HAL_UARTEx_SetTxFifoThreshold(&huart3, UART_TXFIFO_THRESHOLD_1_8) != HAL_OK)
  {
    Error_Handler();
  }
  if (HAL_UARTEx_SetRxFifoThreshold(&huart3, UART_RXFIFO_THRESHOLD_1_8) != HAL_OK)
  {
    Error_Handler();
  }
  if (HAL_UARTEx_DisableFifoMode(&huart3) != HAL_OK)
  {
    Error_Handler();
  }

}

static void MX_GPIO_Init(void)
{

  /* GPIO Ports Clock Enable */
  __HAL_RCC_GPIOH_CLK_ENABLE();
  __HAL_RCC_GPIOC_CLK_ENABLE();
  __HAL_RCC_GPIOA_CLK_ENABLE();
  __HAL_RCC_GPIOB_CLK_ENABLE();
  __HAL_RCC_GPIOE_CLK_ENABLE();
  __HAL_RCC_GPIOD_CLK_ENABLE();

}

void Error_Handler(void)
{
  /* USER CODE BEGIN Error_Handler_Debug */
//  /* User can add his own implementation to report the HAL error return state */
//  __disable_irq();
//  while (1)
//  {
//  }
  /* USER CODE END Error_Handler_Debug */
}
